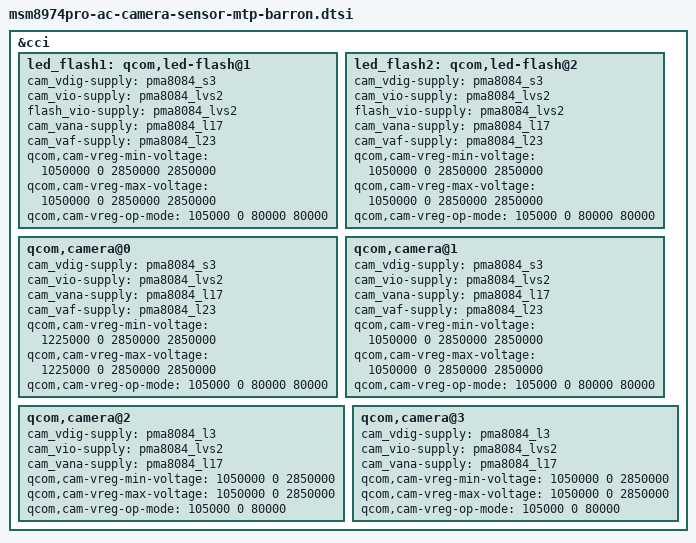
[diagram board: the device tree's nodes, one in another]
/*
 * Copyright (c) 2012-2013, The Linux Foundation. All rights reserved.
 *
 * This program is free software; you can redistribute it and/or modify
 * it under the terms of the GNU General Public License version 2 and
 * only version 2 as published by the Free Software Foundation.
 *
 * This program is distributed in the hope that it will be useful,
 * but WITHOUT ANY WARRANTY; without even the implied warranty of
 * MERCHANTABILITY or FITNESS FOR A PARTICULAR PURPOSE.  See the
 * GNU General Public License for more details.
 */

/*
 * Created by ZTE_JIA_20130828, jia.jia
 *
 * To fix compiling error only
 */

/*
 * Differential configuration of camera sensor
 *
 * See: arch/arm/boot/dts/msm8974-camera.dtsi
 *      arch/arm/boot/dts/msm8974-camera-sensor-mtp.dtsi
 */
// --->
&cci {
	/*
	 * Support for AD adp1650
	 */
	led_flash1: qcom,led-flash@1 {
		/*
		 * VDD configuration
		 */
		cam_vdig-supply = <&pma8084_s3>;
		cam_vio-supply = <&pma8084_lvs2>;
		flash_vio-supply = <&pma8084_lvs2>;
		cam_vana-supply = <&pma8084_l17>;
		cam_vaf-supply = <&pma8084_l23>;
		qcom,cam-vreg-min-voltage = <1050000 0 2850000 2850000>;
		qcom,cam-vreg-max-voltage = <1050000 0 2850000 2850000>;
		qcom,cam-vreg-op-mode = <105000 0 80000 80000>;
	};

	/*
	 * Support for TI lm3642
	 */
	led_flash2: qcom,led-flash@2 {
		/*
		 * VDD configuration
		 */
		cam_vdig-supply = <&pma8084_s3>;
		cam_vio-supply = <&pma8084_lvs2>;
		flash_vio-supply = <&pma8084_lvs2>;
		cam_vana-supply = <&pma8084_l17>;
		cam_vaf-supply = <&pma8084_l23>;
		qcom,cam-vreg-min-voltage = <1050000 0 2850000 2850000>;
		qcom,cam-vreg-max-voltage = <1050000 0 2850000 2850000>;
		qcom,cam-vreg-op-mode = <105000 0 80000 80000>;
	};

	/*
	 * Support for Sony imx091 13Mp
	 *
	 * 'qcom,camera@X' & 'reg = <0xX>': index of camera sensor for mclk
	 * refer to kernel/arch/arm/mach-msm/clock-8974.c
	 *
	 * 'qcom,csid-sd-index' should be set as same as 'qcom,csiphy-sd-index'
	 * for rear/front camera, otherwise 'csid_open' will return error.
	 */
	qcom,camera@0 {
		/*
		 * VDD configuration
		 */
		cam_vdig-supply = <&pma8084_s3>;
		cam_vio-supply = <&pma8084_lvs2>;
		cam_vana-supply = <&pma8084_l17>;
		cam_vaf-supply = <&pma8084_l23>;
		qcom,cam-vreg-min-voltage = <1225000 0 2850000 2850000>;
		qcom,cam-vreg-max-voltage = <1225000 0 2850000 2850000>;
		qcom,cam-vreg-op-mode = <105000 0 80000 80000>;
	};

	/*
	 * Support for Sony imx135 13Mp
	 *
	 * 'qcom,camera@X' & 'reg = <0xX>': index of camera sensor for mclk
	 * refer to kernel/arch/arm/mach-msm/clock-8974.c
	 *
	 * 'qcom,csid-sd-index' should be set as same as 'qcom,csiphy-sd-index'
	 * for rear/front camera, otherwise 'csid_open' will return error.
	 */
	qcom,camera@1 {
		/*
		 * VDD configuration
		 */
		cam_vdig-supply = <&pma8084_s3>;
		cam_vio-supply = <&pma8084_lvs2>;
		cam_vana-supply = <&pma8084_l17>;
		cam_vaf-supply = <&pma8084_l23>;
		qcom,cam-vreg-min-voltage = <1050000 0 2850000 2850000>;
		qcom,cam-vreg-max-voltage = <1050000 0 2850000 2850000>;
		qcom,cam-vreg-op-mode = <105000 0 80000 80000>;
	};

	/*
	 * Support for OV ov9740 720p
	 *
	 * 'qcom,camera@X' & 'reg = <0xX>': index of camera sensor for mclk
	 * refer to kernel/arch/arm/mach-msm/clock-8974.c
	 *
	 * 'qcom,csid-sd-index' should be set as same as 'qcom,csiphy-sd-index'
	 * for rear/front camera, otherwise 'csid_open' will return error.
	 */
	qcom,camera@2 {
		/*
		 * VDD configuration
		 */
		cam_vdig-supply = <&pma8084_l3>;
		cam_vio-supply = <&pma8084_lvs2>;
		cam_vana-supply = <&pma8084_l17>;
		qcom,cam-vreg-min-voltage = <1050000 0 2850000>;
		qcom,cam-vreg-max-voltage = <1050000 0 2850000>;
		qcom,cam-vreg-op-mode = <105000 0 80000>;
	};

	/*
	 * Support for Sony imx132 2.4Mp
	 *
	 * 'qcom,camera@X' & 'reg = <0xX>': index of camera sensor for mclk
	 * refer to kernel/arch/arm/mach-msm/clock-8974.c
	 *
	 * 'qcom,csid-sd-index' should be set as same as 'qcom,csiphy-sd-index'
	 * for rear/front camera, otherwise 'csid_open' will return error.
	 */
	qcom,camera@3 {
		/*
		 * VDD configuration
		 */
		cam_vdig-supply = <&pma8084_l3>;
		cam_vio-supply = <&pma8084_lvs2>;
		cam_vana-supply = <&pma8084_l17>;
		qcom,cam-vreg-min-voltage = <1050000 0 2850000>;
		qcom,cam-vreg-max-voltage = <1050000 0 2850000>;
		qcom,cam-vreg-op-mode = <105000 0 80000>;
	};
// <---
};
